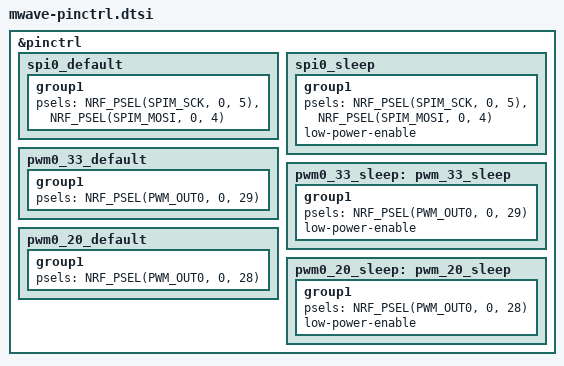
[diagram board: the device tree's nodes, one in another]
/*
 * Copyright (c) 2024 The ZMK Contributors
 * SPDX-License-Identifier: MIT
 */

&pinctrl {
    spi0_default: spi0_default {
        group1 {
            psels = <NRF_PSEL(SPIM_SCK, 0, 5)>,
                <NRF_PSEL(SPIM_MOSI, 0, 4)>;
        };
    };

    spi0_sleep: spi0_sleep {
        group1 {
            psels = <NRF_PSEL(SPIM_SCK, 0, 5)>,
                <NRF_PSEL(SPIM_MOSI, 0, 4)>;
            low-power-enable;
        };
    };
    pwm0_33_default: pwm0_33_default {
        group1 {
            psels = <NRF_PSEL(PWM_OUT0, 0, 29)>;
        };
    };
    pwm0_33_sleep: pwm_33_sleep {
        group1 {
            psels = <NRF_PSEL(PWM_OUT0, 0, 29)>;
            low-power-enable;
        };
    };
    pwm0_20_default: pwm0_20_default {
        group1 {
            psels = <NRF_PSEL(PWM_OUT0, 0, 28)>;
        };
    };
    pwm0_20_sleep: pwm_20_sleep {
        group1 {
            psels = <NRF_PSEL(PWM_OUT0, 0, 28)>;
            low-power-enable;
        };
    };
};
